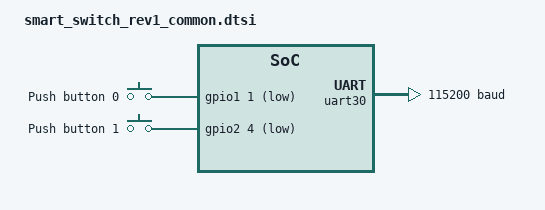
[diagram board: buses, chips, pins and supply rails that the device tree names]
/*
 * Copyright (c) 2024 Nordic Semiconductor ASA
 *
 * SPDX-License-Identifier: Apache-2.0
 */

#include "smart_switch_rev1_pinctrl.dtsi"

/ {
	leds {
		// Remove once nrf/samples/matter/common is moved to our code base
		compatible = "gpio-leds";
	};

	buttons {
		compatible = "gpio-keys";

		button0: button_0 {
			gpios = <&gpio1 1 (GPIO_ACTIVE_LOW)>;
			label = "Push button 0";
			zephyr,code = <INPUT_KEY_0>;
		};

		button1: button_1 {
			gpios = <&gpio2 4 (GPIO_ACTIVE_LOW)>;
			label = "Push button 1";
			zephyr,code = <INPUT_KEY_1>;
		};
	};

	aliases {
		sw0 = &button0;
		sw1 = &button1;
		watchdog0 = &wdt31;
	};
};

/* We're required to use uart30 because of modules/tee/tf-m/trusted-firmware-m/platform/ext/target/nordic_nrf/common/nrf54l/config.cmake */
&uart30 {
	current-speed = <115200>;
	pinctrl-0 = <&uart30_default>;
	pinctrl-1 = <&uart30_sleep>;
	pinctrl-names = "default", "sleep";
};

&hfxo {
	startup-time-us = <854>;
};

/* Get a node label for wi-fi spi to use in shield files */
wifi_spi: &spi22 {};
